# YTM32B1MD2 register map
Vendor: YTMicro; File version: 1.0
CPU: CM33 r0p4, little endian, MPU, FPU, 2 interrupt priority bits
Registers are 32-bit, read-write, reset 0x0 unless marked. A register's access mark holds for its fields unless they carry their own. Offsets are from the block's base; [hi:lo] are bit positions; {n}, {i} and the like mark numbered series.

## SCU — System Clock Unit of Microcontroller
Base 0x4007C000; register names take the prefix SCU_
0x00 CLKS — The register contains clock select bits.
  [1:0] CLKSRCSEL — System Clock Source selection bits.
    0=Select FIRC as system clock source; 1=Select PLL as system clock source; 2=Select FXOSC as system clock source; 3=Select SIRC as system clock source
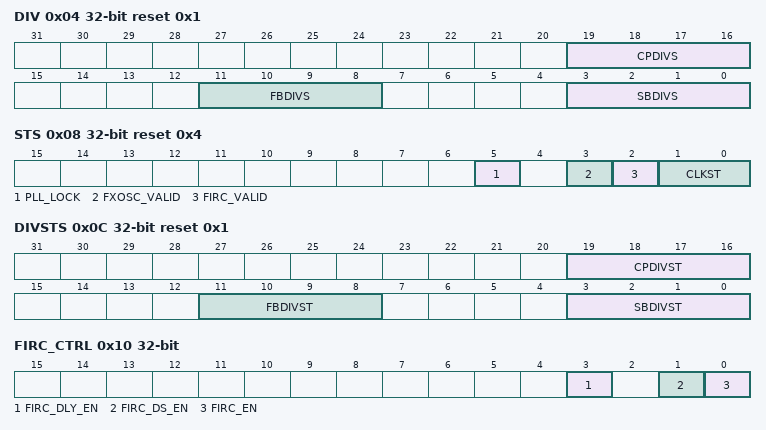
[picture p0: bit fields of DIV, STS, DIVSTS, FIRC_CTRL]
0x04 DIV reset 0x1 — System Clock Divider
  [all] fields
    {v}=Divide by {v+1} (v=0..15)
  [19:16] CPDIVS — Core Platform Clock Divider Value
  [11:8] FBDIVS — Fast Bus Clock Divider Value
  [3:0] SBDIVS — Slow Bus Clock Divider Value
0x08 STS ro reset 0x4 — System Clock Unit Status register
  [5] PLL_LOCK
    0=PLL unlocked; 1=PLL locked
  [3] FXOSC_VALID rw — Indicates FXOSC Clock is valid.
    0=FXOSC Clock invalid; 1=FXOSC Clock valid
  [2] FIRC_VALID rw — Indicates FIRC Clock is valid.
    0=FIRC Clock invalid; 1=FIRC Clock valid
  [1:0] CLKST rw — Indicats System Clock Source Selection status.
    0=FIRC is selected as system clock source; 1=PLL is selected as system clock source; 2=FXOSC is selected as system clock source; 3=SIRC is selected as system clock source
0x0C DIVSTS ro reset 0x1 — System Clock Unit clock divider status
  [all] fields
    {v}=Divide by {v+1} (v=0..15)
  [19:16] CPDIVST rw — Core Platform Clock Divider Value
  [11:8] FBDIVST rw — Fast Bus Clock Divider Value
  [3:0] SBDIVST rw — Slow Bus Clock Divider Value
0x10 FIRC_CTRL — FIRC control register
  [3] FIRC_DLY_EN — Delay FIRC clock out.
    0=Disable FIRC clock out delay; 1=Enable FIRC clock out delay
  [1] FIRC_DS_EN — Enable FIRC when chip enters Deepsleep mode.
    0=Disable FIRC when chip enters Deepsleep mode; 1=Enable FIRC when chip enters Deepsleep mode
  [0] FIRC_EN — Enable FIRC regardless it is selected as system clock source.
    0=Disable FIRC if it is not selected as system clock source; 1=Enable FIRC regardless it is selected as system clock or not
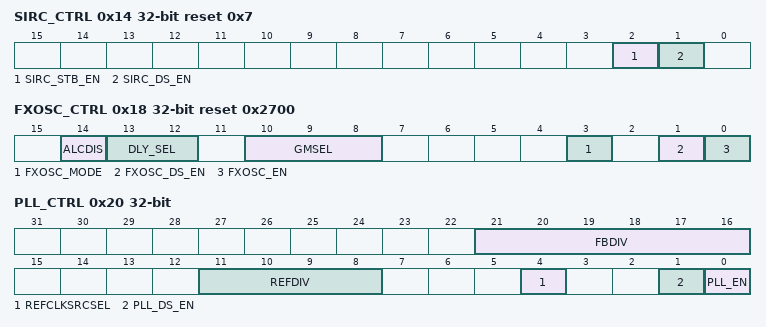
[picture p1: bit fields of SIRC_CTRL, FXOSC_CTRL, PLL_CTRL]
0x14 SIRC_CTRL reset 0x7 — SIRC control register
  [2] SIRC_STB_EN — Enable SIRC when chip enters Standby mode.
    0=Disable SIRC when chip enters Standby mode; 1=Enable SIRC when chip enters Standby mode
  [1] SIRC_DS_EN — Enable SIRC when chip enters Deepsleep mode.
    0=Disable SIRC when chip enters Deepsleep mode; 1=Enable SIRC when chip enters Deepsleep mode
0x18 FXOSC_CTRL reset 0x2700 — FXOSC control register
  [14] ALCDIS — This bit should not be changed when FXOSC_VALID is high
  [13:12] DLY_SEL — FXOSC clock output delay select.
    0=4096 cycles; 1=8192 cycles; 2=16384 cycles (default); 3=32768 cycles
  [10:8] GMSEL — FXOSC gain select for different oscillators. Higher gain value results higher power and better performance, it only impact FXOSC oscillator mode, and it should not be changed when FXOSC_VALID is high
    1=used for 4MHz-6MHz oscillator; 2=used for 6MHz-8MHz oscillator; 3=used for 8MHz-12MHz oscillator; 4=used for 12MHz-32MHz oscillator; 5=used for 32MHz-40MHz oscillator; 6=used for 32MHz-40MHz oscillator; 7=used for 32MHz-40MHz oscillator
  [3] FXOSC_MODE — Enable/Disable FXOSC oscillator mode
    0=Disable FXOSC oscillator mode; 1=Enable FXOSC oscillator mode
  [1] FXOSC_DS_EN — Enable FXOSC when chip enters Deepsleep mode.
    0=Disable FXOSC when chip enters Deepsleep mode; 1=Enable FXOSC when chip enters Deepsleep mode
  [0] FXOSC_EN — Enable Fast crystal osc regardless it is selected as system clock source.
    0=Disable FXOSC if it is not selected as system clock source; 1=Enable FXOSC regardless it is selected as system clock or not
0x20 PLL_CTRL — System Clock Unit PLL control register, changes to this register should be done when PLL is disabled to prevent glitches to system clock source.
  [21:16] FBDIV — The FBDIV bits establish the value of the divider in th PLL feedabck loop. Please refer to \hyperref[phase-locked-loop-clockpll]{Phase-Locked Loop Clock(PLL)}.
  [11:8] REFDIV — Selects the amount to divide down the reference clock for the PLL. Please refer to \hyperref[phase-locked-loop-clockpll]{Phase-Locked Loop Clock(PLL)}.
  [4] REFCLKSRCSEL — PLL reference clock source select bit
    0=Select FXOSC as PLL reference clock; 1=Select FIRC as PLL reference clock
  [1] PLL_DS_EN — Enable/Disable PLL when chip enters Deepsleep mode.
    0=Disable PLL when chip enters Deepsleep mode; 1=Enable PLL when chip enters Deepsleep mode
  [0] PLL_EN — Enable/Disable PLL regardless it is selected as system clock source.
    0=Disable PLL if it is not selected as system clock source; 1=Enable PLL regardless it is selected as system clock or not
